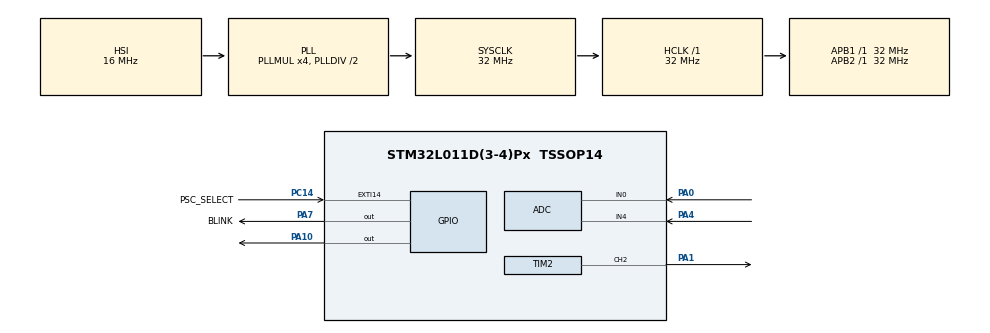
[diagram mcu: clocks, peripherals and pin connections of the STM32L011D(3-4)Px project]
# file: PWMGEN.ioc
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ADC.ContinuousConvMode=ENABLE
ADC.DMAContinuousRequests=ENABLE
ADC.Overrun=ADC_OVR_DATA_OVERWRITTEN
ADC.OversamplingMode=ENABLE
ADC.Ratio=ADC_OVERSAMPLING_RATIO_64
ADC.RightBitShift=ADC_RIGHTBITSHIFT_5
Dma.ADC.0.Direction=DMA_PERIPH_TO_MEMORY
Dma.ADC.0.Instance=DMA1_Channel1
Dma.ADC.0.MemDataAlignment=DMA_MDATAALIGN_WORD
Dma.ADC.0.MemInc=DMA_MINC_ENABLE
Dma.ADC.0.Mode=DMA_CIRCULAR
Dma.ADC.0.PeriphDataAlignment=DMA_PDATAALIGN_WORD
Dma.ADC.0.PeriphInc=DMA_PINC_DISABLE
Dma.ADC.0.Priority=DMA_PRIORITY_LOW
Dma.Request0=ADC
LPTIM1.ClockPrescaler=LPTIM_PRESCALER_DIV128
LPTIM1.UpdateMode=LPTIM_UPDATE_ENDOFPERIOD
Mcu.Family=STM32L0
Mcu.Name=STM32L011D(3-4)Px
Mcu.Package=TSSOP14
NVIC.DMA1_Channel1_IRQn=true\:0\:0\:true\:false\:true\:false\:true
NVIC.EXTI4_15_IRQn=true\:0\:0\:false\:false\:true\:true\:true
NVIC.LPTIM1_IRQn=true\:0\:0\:true\:false\:true\:true\:true
NVIC.TIM21_IRQn=true\:0\:0\:true\:false\:true\:true\:true
PA0-CK_IN.Mode=IN0
PA0-CK_IN.Signal=ADC_IN0
PA1.Signal=S_TIM2_CH2
PA10.GPIO_PuPd=GPIO_PULLUP
PA10.PinState=GPIO_PIN_SET
PA10.Signal=GPIO_Output
PA13.Mode=Serial_Wire
PA13.Signal=SYS_SWDIO
PA14.Mode=Serial_Wire
PA14.Signal=SYS_SWCLK
PA4.Mode=IN4
PA4.Signal=ADC_IN4
PA7.GPIO_Label=BLINK
PA7.GPIO_PuPd=GPIO_PULLUP
PA7.PinState=GPIO_PIN_SET
PA7.Signal=GPIO_Output
PC14-OSC32_IN.GPIO_Label=PSC_SELECT
PC14-OSC32_IN.GPIO_ModeDefaultEXTI=GPIO_MODE_IT_FALLING
PC14-OSC32_IN.GPIO_PuPd=GPIO_PULLUP
PC14-OSC32_IN.Signal=GPXTI14
ProjectManager.HeapSize=0x200
ProjectManager.StackSize=0x400
ProjectManager.TargetToolchain=TrueSTUDIO
RCC.AHBFreq_Value=32000000
RCC.APB1Freq_Value=32000000
RCC.APB1TimFreq_Value=32000000
RCC.APB2Freq_Value=32000000
RCC.APB2TimFreq_Value=32000000
RCC.HCLKFreq_Value=32000000
RCC.HSE_VALUE=8000000
RCC.HSI16_VALUE=16000000
RCC.HSI_VALUE=16000000
RCC.LSE_VALUE=32768
RCC.MSI_VALUE=2097000
RCC.PLLMUL=RCC_PLLMUL_4
RCC.SYSCLKFreq_VALUE=32000000
RCC.SYSCLKSource=RCC_SYSCLKSOURCE_PLLCLK
RCC.VCOOutputFreq_Value=64000000
SH.S_TIM2_CH2.0=TIM2_CH2,PWM Generation2 CH2
TIM2.AutoReloadPreload=TIM_AUTORELOAD_PRELOAD_ENABLE
TIM2.Channel-PWM\ Generation2\ CH2=TIM_CHANNEL_2
TIM2.ClockDivision=TIM_CLOCKDIVISION_DIV1
TIM2.CounterMode=TIM_COUNTERMODE_CENTERALIGNED2
TIM2.Period=1023
TIM2.Prescaler=16
TIM2.Pulse-PWM\ Generation2\ CH2=2047
TIM2.TIM_MasterOutputTrigger=TIM_TRGO_UPDATE
TIM21.AutoReloadPreload=TIM_AUTORELOAD_PRELOAD_ENABLE
TIM21.Period=1024
TIM21.Prescaler=16
TIM21.TIM_MasterOutputTrigger=TIM_TRGO_RESET
VP_LPTIM1_VS_LPTIM_counterModeInternalClock.Mode=Counts__internal_clock_event_00
VP_TIM21_VS_ClockSourceINT.Mode=Internal
VP_TIM2_VS_ClockSourceINT.Mode=Internal
board=custom

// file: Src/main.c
/* USER CODE BEGIN Header */
/**
  ******************************************************************************
  * @file           : main.c
  * @brief          : Main program body
  ******************************************************************************
  * @attention
  *
  * <h2><center>&copy; Copyright (c) 2019 STMicroelectronics.
  * All rights reserved.</center></h2>
  *
  * This software component is licensed by ST under BSD 3-Clause license,
  * the "License"; You may not use this file except in compliance with the
  * License. You may obtain a copy of the License at:
  *                        opensource.org/licenses/BSD-3-Clause
  *
  ******************************************************************************
  */
/* USER CODE END Header */

#include "main.h"
#include "adc.h"
#include "dma.h"
#include "lptim.h"
#include "tim.h"
#include "gpio.h"

/* USER CODE BEGIN PV */
uint32_t input[8] = {0};
/* USER CODE END PV */

void SystemClock_Config(void);

int main(void)
{

  /* MCU Configuration--------------------------------------------------------*/

  /* Reset of all peripherals, Initializes the Flash interface and the Systick. */
  HAL_Init();

  /* Configure the system clock */
  SystemClock_Config();

  /* Initialize all configured peripherals */
  MX_GPIO_Init();
  MX_DMA_Init();
  MX_TIM2_Init();
  MX_LPTIM1_Init();
  MX_TIM21_Init();
  MX_ADC_Init();
  /* USER CODE BEGIN 2 */
  //LL_TIM_EnableCounter(TIM2);
  //LL_TIM_EnableIT_UPDATE(TIM2);
  //HAL_TIM_Base_Start_IT(&htim2);

  // TIMERS must be started before ADC
  HAL_TIM_PWM_Start_IT(&htim2, TIM_CHANNEL_2);
  HAL_TIM_Base_Start_IT(&htim21);
  HAL_LPTIM_TimeOut_Start_IT(&hlptim1, 8192, 8192);

  HAL_ADCEx_Calibration_Start(&hadc, ADC_SINGLE_ENDED);
  HAL_ADC_Start_DMA(&hadc, input, 8);

  /* USER CODE END 2 */

  /* Infinite loop */
  /* USER CODE BEGIN WHILE */
  while (1)
  {

//		HAL_Delay(10);

    /* USER CODE END WHILE */

  }
}

void SystemClock_Config(void)
{
  RCC_OscInitTypeDef RCC_OscInitStruct = {0};
  RCC_ClkInitTypeDef RCC_ClkInitStruct = {0};
  RCC_PeriphCLKInitTypeDef PeriphClkInit = {0};

  /** Configure the main internal regulator output voltage
  */
  __HAL_PWR_VOLTAGESCALING_CONFIG(PWR_REGULATOR_VOLTAGE_SCALE1);
  /** Initializes the CPU, AHB and APB busses clocks
  */
  RCC_OscInitStruct.OscillatorType = RCC_OSCILLATORTYPE_HSI;
  RCC_OscInitStruct.HSIState = RCC_HSI_ON;
  RCC_OscInitStruct.HSICalibrationValue = RCC_HSICALIBRATION_DEFAULT;
  RCC_OscInitStruct.PLL.PLLState = RCC_PLL_ON;
  RCC_OscInitStruct.PLL.PLLSource = RCC_PLLSOURCE_HSI;
  RCC_OscInitStruct.PLL.PLLMUL = RCC_PLLMUL_4;
  RCC_OscInitStruct.PLL.PLLDIV = RCC_PLLDIV_2;
  if (HAL_RCC_OscConfig(&RCC_OscInitStruct) != HAL_OK)
  {
    Error_Handler();
  }
  /** Initializes the CPU, AHB and APB busses clocks
  */
  RCC_ClkInitStruct.ClockType = RCC_CLOCKTYPE_HCLK|RCC_CLOCKTYPE_SYSCLK
                              |RCC_CLOCKTYPE_PCLK1|RCC_CLOCKTYPE_PCLK2;
  RCC_ClkInitStruct.SYSCLKSource = RCC_SYSCLKSOURCE_PLLCLK;
  RCC_ClkInitStruct.AHBCLKDivider = RCC_SYSCLK_DIV1;
  RCC_ClkInitStruct.APB1CLKDivider = RCC_HCLK_DIV1;
  RCC_ClkInitStruct.APB2CLKDivider = RCC_HCLK_DIV1;

  if (HAL_RCC_ClockConfig(&RCC_ClkInitStruct, FLASH_LATENCY_1) != HAL_OK)
  {
    Error_Handler();
  }
  PeriphClkInit.PeriphClockSelection = RCC_PERIPHCLK_LPTIM1;
  PeriphClkInit.LptimClockSelection = RCC_LPTIM1CLKSOURCE_PCLK;

  if (HAL_RCCEx_PeriphCLKConfig(&PeriphClkInit) != HAL_OK)
  {
    Error_Handler();
  }
}

void Error_Handler(void)
{
}

/************************ (C) COPYRIGHT STMicroelectronics *****END OF FILE****/
